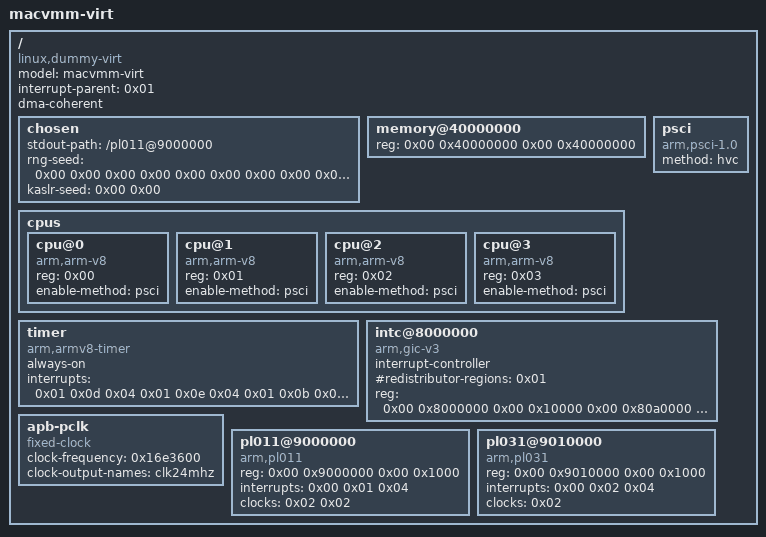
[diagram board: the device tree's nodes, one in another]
/dts-v1/;

/ {
	compatible = "linux,dummy-virt";
	model = "macvmm-virt";
	#address-cells = <0x02>;
	#size-cells = <0x02>;
	interrupt-parent = <0x01>;
	dma-coherent;

	chosen {
		stdout-path = "/pl011@9000000";
		rng-seed = <0x00 0x00 0x00 0x00 0x00 0x00 0x00 0x00 0x00 0x00 0x00 0x00 0x00 0x00 0x00 0x00>;
		kaslr-seed = <0x00 0x00>;
	};

	memory@40000000 {
		device_type = "memory";
		reg = <0x00 0x40000000 0x00 0x40000000>;
	};

	cpus {
		#address-cells = <0x01>;
		#size-cells = <0x00>;

		cpu@0 {
			device_type = "cpu";
			compatible = "arm,arm-v8";
			reg = <0x00>;
			enable-method = "psci";
		};

		cpu@1 {
			device_type = "cpu";
			compatible = "arm,arm-v8";
			reg = <0x01>;
			enable-method = "psci";
		};

		cpu@2 {
			device_type = "cpu";
			compatible = "arm,arm-v8";
			reg = <0x02>;
			enable-method = "psci";
		};

		cpu@3 {
			device_type = "cpu";
			compatible = "arm,arm-v8";
			reg = <0x03>;
			enable-method = "psci";
		};
	};

	psci {
		compatible = "arm,psci-1.0", "arm,psci-0.2", "arm,psci";
		method = "hvc";
	};

	timer {
		compatible = "arm,armv8-timer", "arm,armv7-timer";
		always-on;
		interrupts = <0x01 0x0d 0x04 0x01 0x0e 0x04 0x01 0x0b 0x04 0x01 0x0a 0x04>;
	};

	intc@8000000 {
		compatible = "arm,gic-v3";
		#interrupt-cells = <0x03>;
		interrupt-controller;
		#address-cells = <0x02>;
		#size-cells = <0x02>;
		ranges;
		#redistributor-regions = <0x01>;
		reg = <0x00 0x8000000 0x00 0x10000 0x00 0x80a0000 0x00 0x80000>;
		phandle = <0x01>;
	};

	apb-pclk {
		compatible = "fixed-clock";
		#clock-cells = <0x00>;
		clock-frequency = <0x16e3600>;
		clock-output-names = "clk24mhz";
		phandle = <0x02>;
	};

	pl011@9000000 {
		compatible = "arm,pl011", "arm,primecell";
		reg = <0x00 0x9000000 0x00 0x1000>;
		interrupts = <0x00 0x01 0x04>;
		clocks = <0x02 0x02>;
		clock-names = "uartclk", "apb_pclk";
	};

	pl031@9010000 {
		compatible = "arm,pl031", "arm,primecell";
		reg = <0x00 0x9010000 0x00 0x1000>;
		interrupts = <0x00 0x02 0x04>;
		clocks = <0x02>;
		clock-names = "apb_pclk";
	};
};
